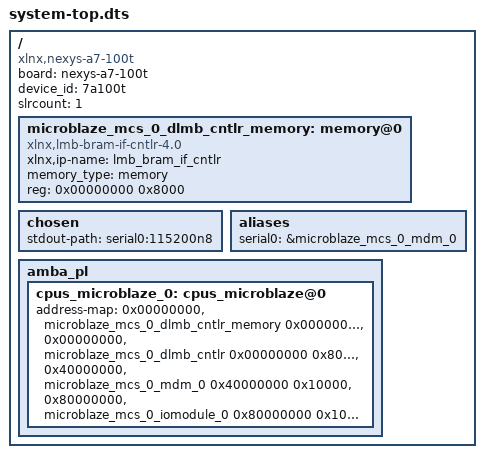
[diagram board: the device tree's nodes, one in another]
/dts-v1/;
#include "pl.dtsi"
/ {
	board = "nexys-a7-100t";
	compatible = "xlnx,nexys-a7-100t";
	device_id = "7a100t";
	#address-cells = <1>;
	#size-cells = <1>;
	slrcount = <1>;
	microblaze_mcs_0_dlmb_cntlr_memory: memory@0 {
		compatible = "xlnx,lmb-bram-if-cntlr-4.0";
		xlnx,ip-name = "lmb_bram_if_cntlr";
		device_type = "memory";
		memory_type = "memory";
		reg = <0x00000000 0x8000>;
	};
	chosen {
		stdout-path = "serial0:115200n8";
	};
	aliases {
		serial0 = &microblaze_mcs_0_mdm_0;
	};
	amba_pl: amba_pl {
		cpus_microblaze_0: cpus_microblaze@0 {
			address-map = <0x00000000 &microblaze_mcs_0_dlmb_cntlr_memory 0x00000000 0x8000>, 
			      <0x00000000 &microblaze_mcs_0_dlmb_cntlr 0x00000000 0x8000>, 
			      <0x40000000 &microblaze_mcs_0_mdm_0 0x40000000 0x10000>, 
			      <0x80000000 &microblaze_mcs_0_iomodule_0 0x80000000 0x10000>;
			#ranges-address-cells = <0x1>;
			#ranges-size-cells = <0x1>;
		};
	};
};
